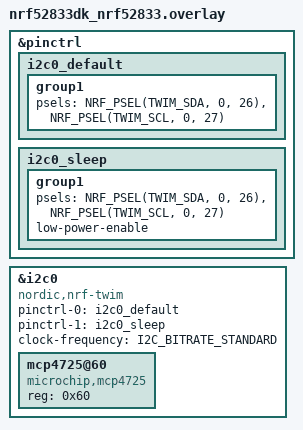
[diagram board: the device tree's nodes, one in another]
/*
 * Device Tree Overlay for MCP4725 DAC on I2C
 * Enables TWIM0 (I2C0) for DAC communication
 */

&pinctrl {
    i2c0_default: i2c0_default {
        group1 {
            psels = <NRF_PSEL(TWIM_SDA, 0, 26)>,
                    <NRF_PSEL(TWIM_SCL, 0, 27)>;
        };
    };

    i2c0_sleep: i2c0_sleep {
        group1 {
            psels = <NRF_PSEL(TWIM_SDA, 0, 26)>,
                    <NRF_PSEL(TWIM_SCL, 0, 27)>;
            low-power-enable;
        };
    };
};

&i2c0 {
    compatible = "nordic,nrf-twim";
    status = "okay";
    pinctrl-0 = <&i2c0_default>;
    pinctrl-1 = <&i2c0_sleep>;
    pinctrl-names = "default", "sleep";
    clock-frequency = <I2C_BITRATE_STANDARD>; /* 100 kHz */

    mcp4725@60 {
        compatible = "microchip,mcp4725";
        reg = <0x60>;
        #io-channel-cells = <1>;
    };
};
